# ET6801 register map
Vendor: ETMCU Inc.; File version: v0.0.1
CPU: CM7 r2p1, little endian, MPU, FPU, I-cache, D-cache, ITCM, DTCM, 4 interrupt priority bits
Registers are 32-bit, read-write, reset 0x0 unless marked. A register's access mark holds for its fields unless they carry their own. Offsets are from the block's base; [hi:lo] are bit positions; {n}, {i} and the like mark numbered series.

## AHBDMA0 (part 2 of 2) — Provide an overview of the purpose and functionality of the peripheral: hdmac_cfg
Base 0x40200000
Same registers: AHBDMA1 0x40201000
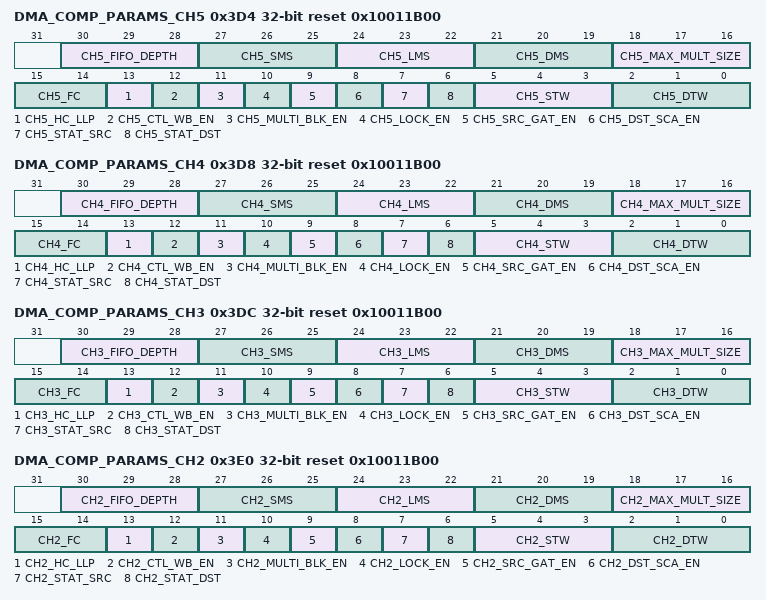
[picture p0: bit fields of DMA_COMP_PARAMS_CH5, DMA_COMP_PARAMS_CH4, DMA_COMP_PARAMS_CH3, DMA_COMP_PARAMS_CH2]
0x3D4 DMA_COMP_PARAMS_CH5 ro reset 0x10011B00 (reset mask 0xFFFFFFFE)
  [30:28] CH5_FIFO_DEPTH — Values: 0x0 (FIFO_DEPTH_8): Channel 5 FIFO depth is 8 bytes 0x1 (FIFO_DEPTH_16): Channel 5 FIFO depth is 16 bytes 0x2 (FIFO_DEPTH_32): Channel 5 FIFO depth is 32 bytes 0x3 (FIFO_DEPTH_64): Channel 5 FIFO depth is 64 bytes 0x4 (FIFO_DEPTH_128): Channel 5 FIFO depth is 128 bytes 0x5 (FIFO_DEPTH_256): Channel 5 FIFO depth is 256 bytes
  [27:25] CH5_SMS — Values: 0x0 (MASTER_1): Hardcode the AHB master 1 interface attached to the source of channel 50x1 (MASTER_2): Hardcode the AHB master 2 interface attached to the source of channel 50x2 (MASTER_3): Hardcode the AHB master 3 interface attached to the source of channel 50x3 (MASTER_4): Hardcode the AHB master 4 interface attached to the source of channel 50x4 (PROGRAMMABLE): Programmable
  [24:22] CH5_LMS — Values: 0x0 (MASTER_1): Hardcode the AHB master 1 interface attached to the LLP peripherals of channel 50x1 (MASTER_2): Hardcode the AHB master 2 interface attached to the LLP peripherals of channel 50x2 (MASTER_3): Hardcode the AHB master 3 interface attached to the LLP peripherals of channel 50x3 (MASTER_4): Hardcode the AHB master 4 interface attached to the LLP peripherals of channel 50x4 (PROGRAMMABLE): Programmable
  [21:19] CH5_DMS — Values: 0x0 (MASTER_1): Hardcode the AHB master 1 interface attached to the channel 5 destination0x1 (MASTER_2): Hardcode the AHB master 2 interface attached to the channel 5 destination0x2 (MASTER_3): Hardcode the AHB master 3 interface attached to the channel 5 destination0x3 (MASTER_4): Hardcode the AHB master 4 interface attached to the channel 5 destination0x4 (PROGRAMMABLE): Programmable
  [18:16] CH5_MAX_MULT_SIZE — Values: 0x0 (MAX_MULT_SIZE_4): Maximum value of burst transaction size that can be programmed for channel 5 is 40x1 (MAX_MULT_SIZE_8): Maximum value of burst transaction size that can be programmed for channel 5 is 80x2 (MAX_MULT_SIZE_16): Maximum value of burst transaction size that can be programmed for channel 5 is 160x3 (MAX_MULT_SIZE_32): Maximum value of burst transaction size that can be programmed for channel 5 is 320x4 (MAX_MULT_SIZE_64): Maximum value of burst transaction size that can be programmed for channel 5 is 640x5 (MAX_MULT_SIZE_128): Maximum value of burst transaction size that can be programmed for channel 5 is 1280x6 (MAX_MULT_SIZE_256): Maximum value of burst transaction size that can be programmed for channel 5 is 2560x7 (RESERVED): Reserved
  [15:14] CH5_FC — Values: 0x0 (FC_DMA): Flow controller is DMA for channel 50x1 (FC_SRC): Flow controller is Source for channel 50x2 (FC_DST): Flow controller is Destination for channel 70x3 (FC_ANY): Flow controller is ANY for channel 5
  [13] CH5_HC_LLP — Values: 0x0 (PROGRAMMABLE): Exclude logic to hardcode Channel 5 LLP register to 00x0 (HARDCODED): Hardcode Channel 5 LLP register to 0
  [12] CH5_CTL_WB_EN — Values: 0x0 (FALSE): Exclude logic to enable control register writeback after each block transfer on channel 50x1 (TRUE): Include logic to enable control register writeback after each block transfer on channel 5
  [11] CH5_MULTI_BLK_EN — Values: 0x0 (FALSE): Exclude logic to enable channel multi-block DMA transfers on channel 50x1 (TRUE): Include logic to enable channel multi-block DMA transfers on channel 5
  [10] CH5_LOCK_EN — Values: 0x0 (FALSE): Exclude logic to enable channel or bus locking on channel 50x1 (TRUE): Include logic to enable channel or bus locking on channel 5
  [9] CH5_SRC_GAT_EN — Values: 0x0 (FALSE): Exclude logic to enable the gather feature on channel 50x1 (TRUE): Include logic to enable the gather feature on channel 5
  [8] CH5_DST_SCA_EN — Values: 0x0 (FALSE): Exclude logic to enable the scatter feature on channel 50x1 (TRUE): Include logic to enable the scatter feature on channel 5
  [7] CH5_STAT_SRC — Values: 0x0 (FALSE): Exclude logic to fetch a status register from source peripheral of channel 5 and write this status information to memory at end of each block transfer0x1 (TRUE): Include logic to fetch a status register from source peripheral of channel 5 and write this status information to memory at end of each block transfer
  [6] CH5_STAT_DST — Values: 0x0 (FALSE): Exclude logic to fetch a status register from destination peripheral of channel 5 and write this status information to memory at end of each block transfer0x1 (TRUE): Include logic to fetch a status register from destination peripheral of channel 5 and write this status information to memory at end of each block transfer
  [5:3] CH5_STW — Values: 0x0 (NO_HARDCODE): No hardcode0x1 (STW_8): Hardcode the channel 5's source transfer width to 8 bits0x2 (STW_16): Hardcode the channel 5's source transfer width to 16 bits0x3 (STW_32): Hardcode the channel 5's source transfer width to 32 bits0x4 (STW_64): Hardcode the channel 5's source transfer width to 64 bits0x5 (STW_128): Hardcode the channel 5's source transfer width to 128 bits0x6 (STW_256): Hardcode the channel 5's source transfer width to 256 bits0x7 (RESERVED): Reserved
  [2:0] CH5_DTW — Values: 0x0 (NO_HARDCODE): NO Hardcode0x1 (DTW_8): Hardcode the channel 5's destination transfer width to 8 bits0x2 (DTW_16): Hardcode the channel 5's destination transfer width to 16 bits0x3 (DTW_32): Hardcode the channel 5's destination transfer width to 32 bits0x4 (DTW_64): Hardcode the channel 5's destination transfer width to 64 bits0x5 (DTW_128): Hardcode the channel 5's destination transfer width to 128 bits0x6 (DTW_256): Hardcode the channel 5's destination transfer width to 256 bits0x7 (RESERVED): Reserved
0x3D8 DMA_COMP_PARAMS_CH4 ro reset 0x10011B00 (reset mask 0xFFFFFFFE)
  [30:28] CH4_FIFO_DEPTH — Values: 0x0 (FIFO_DEPTH_8): Channel 4 FIFO depth is 8 bytes 0x1 (FIFO_DEPTH_16): Channel 4 FIFO depth is 16 bytes 0x2 (FIFO_DEPTH_32): Channel 4 FIFO depth is 32 bytes 0x3 (FIFO_DEPTH_64): Channel 4 FIFO depth is 64 bytes 0x4 (FIFO_DEPTH_128): Channel 4 FIFO depth is 128 bytes 0x5 (FIFO_DEPTH_256): Channel 4 FIFO depth is 256 bytes
  [27:25] CH4_SMS — Values: 0x0 (MASTER_1): Hardcode the AHB master 1 interface attached to the source of channel 40x1 (MASTER_2): Hardcode the AHB master 2 interface attached to the source of channel 40x2 (MASTER_3): Hardcode the AHB master 3 interface attached to the source of channel 40x3 (MASTER_4): Hardcode the AHB master 4 interface attached to the source of channel 40x4 (PROGRAMMABLE): Programmable
  [24:22] CH4_LMS — Values: 0x0 (MASTER_1): Hardcode the AHB master 1 interface attached to the LLP peripherals of channel 40x1 (MASTER_2): Hardcode the AHB master 2 interface attached to the LLP peripherals of channel 40x2 (MASTER_3): Hardcode the AHB master 3 interface attached to the LLP peripherals of channel 40x3 (MASTER_4): Hardcode the AHB master 4 interface attached to the LLP peripherals of channel 40x4 (PROGRAMMABLE): Programmable
  [21:19] CH4_DMS — Values: 0x0 (MASTER_1): Hardcode the AHB master 1 interface attached to the channel 4 destination0x1 (MASTER_2): Hardcode the AHB master 2 interface attached to the channel 4 destination0x2 (MASTER_3): Hardcode the AHB master 3 interface attached to the channel 4 destination0x3 (MASTER_4): Hardcode the AHB master 4 interface attached to the channel 4 destination0x4 (PROGRAMMABLE): Programmable
  [18:16] CH4_MAX_MULT_SIZE — Values: 0x0 (MAX_MULT_SIZE_4): Maximum value of burst transaction size that can be programmed for channel 4 is 40x1 (MAX_MULT_SIZE_8): Maximum value of burst transaction size that can be programmed for channel 4 is 80x2 (MAX_MULT_SIZE_16): Maximum value of burst transaction size that can be programmed for channel 4 is 160x3 (MAX_MULT_SIZE_32): Maximum value of burst transaction size that can be programmed for channel 4 is 320x4 (MAX_MULT_SIZE_64): Maximum value of burst transaction size that can be programmed for channel 4 is 640x5 (MAX_MULT_SIZE_128): Maximum value of burst transaction size that can be programmed for channel 4 is 1280x6 (MAX_MULT_SIZE_256): Maximum value of burst transaction size that can be programmed for channel 4 is 2560x7 (RESERVED): Reserved
  [15:14] CH4_FC — Values: 0x0 (FC_DMA): Flow controller is DMA for channel 40x1 (FC_SRC): Flow controller is Source for channel 40x2 (FC_DST): Flow controller is Destination for channel 70x3 (FC_ANY): Flow controller is ANY for channel 4
  [13] CH4_HC_LLP — Values: 0x0 (PROGRAMMABLE): Exclude logic to hardcode Channel 4 LLP register to 00x0 (HARDCODED): Hardcode Channel 4 LLP register to 0
  [12] CH4_CTL_WB_EN — Values: 0x0 (FALSE): Exclude logic to enable control register writeback after each block transfer on channel 40x1 (TRUE): Include logic to enable control register writeback after each block transfer on channel 4
  [11] CH4_MULTI_BLK_EN — Values: 0x0 (FALSE): Exclude logic to enable channel multi-block DMA transfers on channel 40x1 (TRUE): Include logic to enable channel multi-block DMA transfers on channel 4
  [10] CH4_LOCK_EN — Values: 0x0 (FALSE): Exclude logic to enable channel or bus locking on channel 40x1 (TRUE): Include logic to enable channel or bus locking on channel 4
  [9] CH4_SRC_GAT_EN — Values: 0x0 (FALSE): Exclude logic to enable the gather feature on channel 40x1 (TRUE): Include logic to enable the gather feature on channel 4
  [8] CH4_DST_SCA_EN — Values: 0x0 (FALSE): Exclude logic to enable the scatter feature on channel 40x1 (TRUE): Include logic to enable the scatter feature on channel 4
  [7] CH4_STAT_SRC — Values: 0x0 (FALSE): Exclude logic to fetch a status register from source peripheral of channel 4 and write this status information to memory at end of each block transfer0x1 (TRUE): Include logic to fetch a status register from source peripheral of channel 4 and write this status information to memory at end of each block transfer
  [6] CH4_STAT_DST — Values: 0x0 (FALSE): Exclude logic to fetch a status register from destination peripheral of channel 4 and write this status information to memory at end of each block transfer0x1 (TRUE): Include logic to fetch a status register from destination peripheral of channel 4 and write this status information to memory at end of each block transfer
  [5:3] CH4_STW — Values: 0x0 (NO_HARDCODE): No hardcode0x1 (STW_8): Hardcode the channel 4's source transfer width to 8 bits0x2 (STW_16): Hardcode the channel 4's source transfer width to 16 bits0x3 (STW_32): Hardcode the channel 4's source transfer width to 32 bits0x4 (STW_64): Hardcode the channel 4's source transfer width to 64 bits0x5 (STW_128): Hardcode the channel 4's source transfer width to 128 bits0x6 (STW_256): Hardcode the channel 4's source transfer width to 256 bits0x7 (RESERVED): Reserved
  [2:0] CH4_DTW — Values: 0x0 (NO_HARDCODE): NO Hardcode0x1 (DTW_8): Hardcode the channel 4's destination transfer width to 8 bits0x2 (DTW_16): Hardcode the channel 4's destination transfer width to 16 bits0x3 (DTW_32): Hardcode the channel 4's destination transfer width to 32 bits0x4 (DTW_64): Hardcode the channel 4's destination transfer width to 64 bits0x5 (DTW_128): Hardcode the channel 4's destination transfer width to 128 bits0x6 (DTW_256): Hardcode the channel 4's destination transfer width to 256 bits0x7 (RESERVED): Reserved
0x3DC DMA_COMP_PARAMS_CH3 ro reset 0x10011B00 (reset mask 0xFFFFFFFE)
  [30:28] CH3_FIFO_DEPTH — Values: 0x0 (FIFO_DEPTH_8): Channel 3 FIFO depth is 8 bytes 0x1 (FIFO_DEPTH_16): Channel 3 FIFO depth is 16 bytes 0x2 (FIFO_DEPTH_32): Channel 3 FIFO depth is 32 bytes 0x3 (FIFO_DEPTH_64): Channel 3 FIFO depth is 64 bytes 0x4 (FIFO_DEPTH_128): Channel 3 FIFO depth is 128 bytes 0x5 (FIFO_DEPTH_256): Channel 3 FIFO depth is 256 bytes
  [27:25] CH3_SMS — Values: 0x0 (MASTER_1): Hardcode the AHB master 1 interface attached to the source of channel 30x1 (MASTER_2): Hardcode the AHB master 2 interface attached to the source of channel 30x2 (MASTER_3): Hardcode the AHB master 3 interface attached to the source of channel 30x3 (MASTER_4): Hardcode the AHB master 4 interface attached to the source of channel 30x4 (PROGRAMMABLE): Programmable
  [24:22] CH3_LMS — Values: 0x0 (MASTER_1): Hardcode the AHB master 1 interface attached to the LLP peripherals of channel 30x1 (MASTER_2): Hardcode the AHB master 2 interface attached to the LLP peripherals of channel 30x2 (MASTER_3): Hardcode the AHB master 3 interface attached to the LLP peripherals of channel 30x3 (MASTER_4): Hardcode the AHB master 4 interface attached to the LLP peripherals of channel 30x4 (PROGRAMMABLE): Programmable
  [21:19] CH3_DMS — Values: 0x0 (MASTER_1): Hardcode the AHB master 1 interface attached to the channel 3 destination0x1 (MASTER_2): Hardcode the AHB master 2 interface attached to the channel 3 destination0x2 (MASTER_3): Hardcode the AHB master 3 interface attached to the channel 3 destination0x3 (MASTER_4): Hardcode the AHB master 4 interface attached to the channel 3 destination0x4 (PROGRAMMABLE): Programmable
  [18:16] CH3_MAX_MULT_SIZE — Values: 0x0 (MAX_MULT_SIZE_4): Maximum value of burst transaction size that can be programmed for channel 3 is 40x1 (MAX_MULT_SIZE_8): Maximum value of burst transaction size that can be programmed for channel 3 is 80x2 (MAX_MULT_SIZE_16): Maximum value of burst transaction size that can be programmed for channel 3 is 160x3 (MAX_MULT_SIZE_32): Maximum value of burst transaction size that can be programmed for channel 3 is 320x4 (MAX_MULT_SIZE_64): Maximum value of burst transaction size that can be programmed for channel 3 is 640x5 (MAX_MULT_SIZE_128): Maximum value of burst transaction size that can be programmed for channel 3 is 1280x6 (MAX_MULT_SIZE_256): Maximum value of burst transaction size that can be programmed for channel 3 is 2560x7 (RESERVED): Reserved
  [15:14] CH3_FC — Values: 0x0 (FC_DMA): Flow controller is DMA for channel 30x1 (FC_SRC): Flow controller is Source for channel 30x2 (FC_DST): Flow controller is Destination for channel 70x3 (FC_ANY): Flow controller is ANY for channel 3
  [13] CH3_HC_LLP — Values: 0x0 (PROGRAMMABLE): Exclude logic to hardcode Channel 3 LLP register to 00x0 (HARDCODED): Hardcode Channel 3 LLP register to 0
  [12] CH3_CTL_WB_EN — Values: 0x0 (FALSE): Exclude logic to enable control register writeback after each block transfer on channel 30x1 (TRUE): Include logic to enable control register writeback after each block transfer on channel 3
  [11] CH3_MULTI_BLK_EN — Values: 0x0 (FALSE): Exclude logic to enable channel multi-block DMA transfers on channel 30x1 (TRUE): Include logic to enable channel multi-block DMA transfers on channel 3
  [10] CH3_LOCK_EN — Values: 0x0 (FALSE): Exclude logic to enable channel or bus locking on channel 30x1 (TRUE): Include logic to enable channel or bus locking on channel 3
  [9] CH3_SRC_GAT_EN — Values: 0x0 (FALSE): Exclude logic to enable the gather feature on channel 30x1 (TRUE): Include logic to enable the gather feature on channel 3
  [8] CH3_DST_SCA_EN — Values: 0x0 (FALSE): Exclude logic to enable the scatter feature on channel 30x1 (TRUE): Include logic to enable the scatter feature on channel 3
  [7] CH3_STAT_SRC — Values: 0x0 (FALSE): Exclude logic to fetch a status register from source peripheral of channel 3 and write this status information to memory at end of each block transfer0x1 (TRUE): Include logic to fetch a status register from source peripheral of channel 3 and write this status information to memory at end of each block transfer
  [6] CH3_STAT_DST — Values: 0x0 (FALSE): Exclude logic to fetch a status register from destination peripheral of channel 3 and write this status information to memory at end of each block transfer0x1 (TRUE): Include logic to fetch a status register from destination peripheral of channel 3 and write this status information to memory at end of each block transfer
  [5:3] CH3_STW — Values: 0x0 (NO_HARDCODE): No hardcode0x1 (STW_8): Hardcode the channel 3's source transfer width to 8 bits0x2 (STW_16): Hardcode the channel 3's source transfer width to 16 bits0x3 (STW_32): Hardcode the channel 3's source transfer width to 32 bits0x4 (STW_64): Hardcode the channel 3's source transfer width to 64 bits0x5 (STW_128): Hardcode the channel 3's source transfer width to 128 bits0x6 (STW_256): Hardcode the channel 3's source transfer width to 256 bits0x7 (RESERVED): Reserved
  [2:0] CH3_DTW — Values: 0x0 (NO_HARDCODE): NO Hardcode0x1 (DTW_8): Hardcode the channel 3's destination transfer width to 8 bits0x2 (DTW_16): Hardcode the channel 3's destination transfer width to 16 bits0x3 (DTW_32): Hardcode the channel 3's destination transfer width to 32 bits0x4 (DTW_64): Hardcode the channel 3's destination transfer width to 64 bits0x5 (DTW_128): Hardcode the channel 3's destination transfer width to 128 bits0x6 (DTW_256): Hardcode the channel 3's destination transfer width to 256 bits0x7 (RESERVED): Reserved
0x3E0 DMA_COMP_PARAMS_CH2 ro reset 0x10011B00 (reset mask 0xFFFFFFFE)
  [30:28] CH2_FIFO_DEPTH — Values: 0x0 (FIFO_DEPTH_8): Channel 2 FIFO depth is 8 bytes 0x1 (FIFO_DEPTH_16): Channel 2 FIFO depth is 16 bytes 0x2 (FIFO_DEPTH_32): Channel 2 FIFO depth is 32 bytes 0x3 (FIFO_DEPTH_64): Channel 2 FIFO depth is 64 bytes 0x4 (FIFO_DEPTH_128): Channel 2 FIFO depth is 128 bytes 0x5 (FIFO_DEPTH_256): Channel 2 FIFO depth is 256 bytes
  [27:25] CH2_SMS — Values: 0x0 (MASTER_1): Hardcode the AHB master 1 interface attached to the source of channel 20x1 (MASTER_2): Hardcode the AHB master 2 interface attached to the source of channel 20x2 (MASTER_3): Hardcode the AHB master 3 interface attached to the source of channel 20x3 (MASTER_4): Hardcode the AHB master 4 interface attached to the source of channel 20x4 (PROGRAMMABLE): Programmable
  [24:22] CH2_LMS — Values: 0x0 (MASTER_1): Hardcode the AHB master 1 interface attached to the LLP peripherals of channel 20x1 (MASTER_2): Hardcode the AHB master 2 interface attached to the LLP peripherals of channel 20x2 (MASTER_3): Hardcode the AHB master 3 interface attached to the LLP peripherals of channel 20x3 (MASTER_4): Hardcode the AHB master 4 interface attached to the LLP peripherals of channel 20x4 (PROGRAMMABLE): Programmable
  [21:19] CH2_DMS — Values: 0x0 (MASTER_1): Hardcode the AHB master 1 interface attached to the channel 2 destination0x1 (MASTER_2): Hardcode the AHB master 2 interface attached to the channel 2 destination0x2 (MASTER_3): Hardcode the AHB master 3 interface attached to the channel 2 destination0x3 (MASTER_4): Hardcode the AHB master 4 interface attached to the channel 2 destination0x4 (PROGRAMMABLE): Programmable
  [18:16] CH2_MAX_MULT_SIZE — Values: 0x0 (MAX_MULT_SIZE_4): Maximum value of burst transaction size that can be programmed for channel 2 is 40x1 (MAX_MULT_SIZE_8): Maximum value of burst transaction size that can be programmed for channel 2 is 80x2 (MAX_MULT_SIZE_16): Maximum value of burst transaction size that can be programmed for channel 2 is 160x3 (MAX_MULT_SIZE_32): Maximum value of burst transaction size that can be programmed for channel 2 is 320x4 (MAX_MULT_SIZE_64): Maximum value of burst transaction size that can be programmed for channel 2 is 640x5 (MAX_MULT_SIZE_128): Maximum value of burst transaction size that can be programmed for channel 2 is 1280x6 (MAX_MULT_SIZE_256): Maximum value of burst transaction size that can be programmed for channel 2 is 2560x7 (RESERVED): Reserved
  [15:14] CH2_FC — Values: 0x0 (FC_DMA): Flow controller is DMA for channel 20x1 (FC_SRC): Flow controller is Source for channel 20x2 (FC_DST): Flow controller is Destination for channel 70x3 (FC_ANY): Flow controller is ANY for channel 2
  [13] CH2_HC_LLP — Values: 0x0 (PROGRAMMABLE): Exclude logic to hardcode Channel 2 LLP register to 00x0 (HARDCODED): Hardcode Channel 2 LLP register to 0
  [12] CH2_CTL_WB_EN — Values: 0x0 (FALSE): Exclude logic to enable control register writeback after each block transfer on channel 20x1 (TRUE): Include logic to enable control register writeback after each block transfer on channel 2
  [11] CH2_MULTI_BLK_EN — Values: 0x0 (FALSE): Exclude logic to enable channel multi-block DMA transfers on channel 20x1 (TRUE): Include logic to enable channel multi-block DMA transfers on channel 2
  [10] CH2_LOCK_EN — Values: 0x0 (FALSE): Exclude logic to enable channel or bus locking on channel 20x1 (TRUE): Include logic to enable channel or bus locking on channel 2
  [9] CH2_SRC_GAT_EN — Values: 0x0 (FALSE): Exclude logic to enable the gather feature on channel 20x1 (TRUE): Include logic to enable the gather feature on channel 2
  [8] CH2_DST_SCA_EN — Values: 0x0 (FALSE): Exclude logic to enable the scatter feature on channel 20x1 (TRUE): Include logic to enable the scatter feature on channel 2
  [7] CH2_STAT_SRC — Values: 0x0 (FALSE): Exclude logic to fetch a status register from source peripheral of channel 2 and write this status information to memory at end of each block transfer0x1 (TRUE): Include logic to fetch a status register from source peripheral of channel 2 and write this status information to memory at end of each block transfer
  [6] CH2_STAT_DST — Values: 0x0 (FALSE): Exclude logic to fetch a status register from destination peripheral of channel 2 and write this status information to memory at end of each block transfer0x1 (TRUE): Include logic to fetch a status register from destination peripheral of channel 2 and write this status information to memory at end of each block transfer
  [5:3] CH2_STW — Values: 0x0 (NO_HARDCODE): No hardcode0x1 (STW_8): Hardcode the channel 2's source transfer width to 8 bits0x2 (STW_16): Hardcode the channel 2's source transfer width to 16 bits0x3 (STW_32): Hardcode the channel 2's source transfer width to 32 bits0x4 (STW_64): Hardcode the channel 2's source transfer width to 64 bits0x5 (STW_128): Hardcode the channel 2's source transfer width to 128 bits0x6 (STW_256): Hardcode the channel 2's source transfer width to 256 bits0x7 (RESERVED): Reserved
  [2:0] CH2_DTW — Values: 0x0 (NO_HARDCODE): NO Hardcode0x1 (DTW_8): Hardcode the channel 2's destination transfer width to 8 bits0x2 (DTW_16): Hardcode the channel 2's destination transfer width to 16 bits0x3 (DTW_32): Hardcode the channel 2's destination transfer width to 32 bits0x4 (DTW_64): Hardcode the channel 2's destination transfer width to 64 bits0x5 (DTW_128): Hardcode the channel 2's destination transfer width to 128 bits0x6 (DTW_256): Hardcode the channel 2's destination transfer width to 256 bits0x7 (RESERVED): Reserved
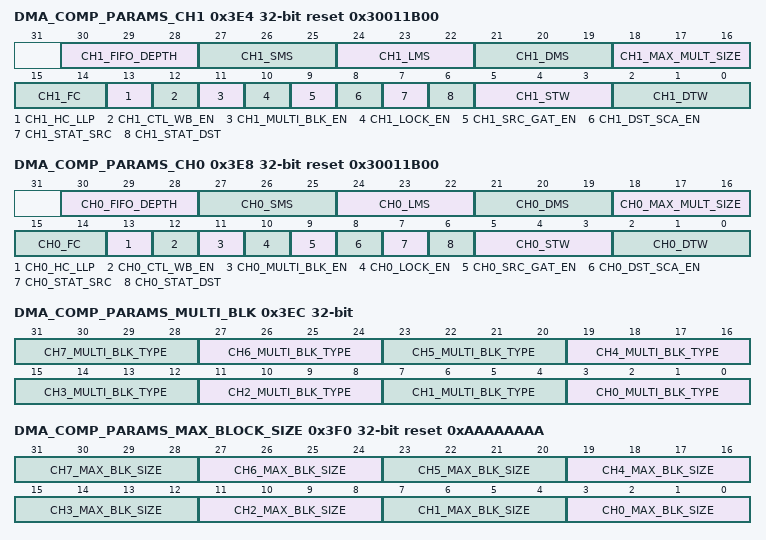
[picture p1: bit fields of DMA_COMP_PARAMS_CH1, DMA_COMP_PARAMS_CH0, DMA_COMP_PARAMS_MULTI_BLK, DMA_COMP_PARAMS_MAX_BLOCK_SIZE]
0x3E4 DMA_COMP_PARAMS_CH1 ro reset 0x30011B00 (reset mask 0xFFFFFFFE)
  [30:28] CH1_FIFO_DEPTH — Values: 0x0 (FIFO_DEPTH_8): Channel 1 FIFO depth is 8 bytes 0x1 (FIFO_DEPTH_16): Channel 1 FIFO depth is 16 bytes 0x2 (FIFO_DEPTH_32): Channel 1 FIFO depth is 32 bytes 0x3 (FIFO_DEPTH_64): Channel 1 FIFO depth is 64 bytes 0x4 (FIFO_DEPTH_128): Channel 1 FIFO depth is 128 bytes 0x5 (FIFO_DEPTH_256): Channel 1 FIFO depth is 256 bytes
  [27:25] CH1_SMS — Values: 0x0 (MASTER_1): Hardcode the AHB master 1 interface attached to the source of channel 10x1 (MASTER_2): Hardcode the AHB master 2 interface attached to the source of channel 10x2 (MASTER_3): Hardcode the AHB master 3 interface attached to the source of channel 10x3 (MASTER_4): Hardcode the AHB master 4 interface attached to the source of channel 10x4 (PROGRAMMABLE): Programmable
  [24:22] CH1_LMS — Values: 0x0 (MASTER_1): Hardcode the AHB master 1 interface attached to the LLP peripherals of channel 10x1 (MASTER_2): Hardcode the AHB master 2 interface attached to the LLP peripherals of channel 10x2 (MASTER_3): Hardcode the AHB master 3 interface attached to the LLP peripherals of channel 10x3 (MASTER_4): Hardcode the AHB master 4 interface attached to the LLP peripherals of channel 10x4 (PROGRAMMABLE): Programmable
  [21:19] CH1_DMS — Values: 0x0 (MASTER_1): Hardcode the AHB master 1 interface attached to the channel 1 destination0x1 (MASTER_2): Hardcode the AHB master 2 interface attached to the channel 1 destination0x2 (MASTER_3): Hardcode the AHB master 3 interface attached to the channel 1 destination0x3 (MASTER_4): Hardcode the AHB master 4 interface attached to the channel 1 destination0x4 (PROGRAMMABLE): Programmable
  [18:16] CH1_MAX_MULT_SIZE — Values: 0x0 (MAX_MULT_SIZE_4): Maximum value of burst transaction size that can be programmed for channel 1 is 40x1 (MAX_MULT_SIZE_8): Maximum value of burst transaction size that can be programmed for channel 1 is 80x2 (MAX_MULT_SIZE_16): Maximum value of burst transaction size that can be programmed for channel 1 is 160x3 (MAX_MULT_SIZE_32): Maximum value of burst transaction size that can be programmed for channel 1 is 320x4 (MAX_MULT_SIZE_64): Maximum value of burst transaction size that can be programmed for channel 1 is 640x5 (MAX_MULT_SIZE_128): Maximum value of burst transaction size that can be programmed for channel 1 is 1280x6 (MAX_MULT_SIZE_256): Maximum value of burst transaction size that can be programmed for channel 1 is 2560x7 (RESERVED): Reserved
  [15:14] CH1_FC — Values: 0x0 (FC_DMA): Flow controller is DMA for channel 10x1 (FC_SRC): Flow controller is Source for channel 10x2 (FC_DST): Flow controller is Destination for channel 70x3 (FC_ANY): Flow controller is ANY for channel 1
  [13] CH1_HC_LLP — Values: 0x0 (PROGRAMMABLE): Exclude logic to hardcode Channel 1 LLP register to 00x0 (HARDCODED): Hardcode Channel 1 LLP register to 0
  [12] CH1_CTL_WB_EN — Values: 0x0 (FALSE): Exclude logic to enable control register writeback after each block transfer on channel 10x1 (TRUE): Include logic to enable control register writeback after each block transfer on channel 1
  [11] CH1_MULTI_BLK_EN — Values: 0x0 (FALSE): Exclude logic to enable channel multi-block DMA transfers on channel 10x1 (TRUE): Include logic to enable channel multi-block DMA transfers on channel 1
  [10] CH1_LOCK_EN — Values: 0x0 (FALSE): Exclude logic to enable channel or bus locking on channel 10x1 (TRUE): Include logic to enable channel or bus locking on channel 1
  [9] CH1_SRC_GAT_EN — Values: 0x0 (FALSE): Exclude logic to enable the gather feature on channel 10x1 (TRUE): Include logic to enable the gather feature on channel 1
  [8] CH1_DST_SCA_EN — Values: 0x0 (FALSE): Exclude logic to enable the scatter feature on channel 10x1 (TRUE): Include logic to enable the scatter feature on channel 1
  [7] CH1_STAT_SRC — Values: 0x0 (FALSE): Exclude logic to fetch a status register from source peripheral of channel 1 and write this status information to memory at end of each block transfer0x1 (TRUE): Include logic to fetch a status register from source peripheral of channel 1 and write this status information to memory at end of each block transfer
  [6] CH1_STAT_DST — Values: 0x0 (FALSE): Exclude logic to fetch a status register from destination peripheral of channel 1 and write this status information to memory at end of each block transfer0x1 (TRUE): Include logic to fetch a status register from destination peripheral of channel 1 and write this status information to memory at end of each block transfer
  [5:3] CH1_STW — Values: 0x0 (NO_HARDCODE): No hardcode0x1 (STW_8): Hardcode the channel 1's source transfer width to 8 bits0x2 (STW_16): Hardcode the channel 1's source transfer width to 16 bits0x3 (STW_32): Hardcode the channel 1's source transfer width to 32 bits0x4 (STW_64): Hardcode the channel 1's source transfer width to 64 bits0x5 (STW_128): Hardcode the channel 1's source transfer width to 128 bits0x6 (STW_256): Hardcode the channel 1's source transfer width to 256 bits0x7 (RESERVED): Reserved
  [2:0] CH1_DTW — Values: 0x0 (NO_HARDCODE): NO Hardcode0x1 (DTW_8): Hardcode the channel 1's destination transfer width to 8 bits0x2 (DTW_16): Hardcode the channel 1's destination transfer width to 16 bits0x3 (DTW_32): Hardcode the channel 1's destination transfer width to 32 bits0x4 (DTW_64): Hardcode the channel 1's destination transfer width to 64 bits0x5 (DTW_128): Hardcode the channel 1's destination transfer width to 128 bits0x6 (DTW_256): Hardcode the channel 1's destination transfer width to 256 bits0x7 (RESERVED): Reserved
0x3E8 DMA_COMP_PARAMS_CH0 ro reset 0x30011B00 (reset mask 0xFFFFFFFE)
  [30:28] CH0_FIFO_DEPTH — Values: 0x0 (FIFO_DEPTH_8): Channel 0 FIFO depth is 8 bytes 0x1 (FIFO_DEPTH_16): Channel 0 FIFO depth is 16 bytes 0x2 (FIFO_DEPTH_32): Channel 0 FIFO depth is 32 bytes 0x3 (FIFO_DEPTH_64): Channel 0 FIFO depth is 64 bytes 0x4 (FIFO_DEPTH_128): Channel 0 FIFO depth is 128 bytes 0x5 (FIFO_DEPTH_256): Channel 0 FIFO depth is 256 bytes
  [27:25] CH0_SMS — Values: 0x0 (MASTER_1): Hardcode the AHB master 1 interface attached to the source of channel 00x1 (MASTER_2): Hardcode the AHB master 2 interface attached to the source of channel 00x2 (MASTER_3): Hardcode the AHB master 3 interface attached to the source of channel 00x3 (MASTER_4): Hardcode the AHB master 4 interface attached to the source of channel 00x4 (PROGRAMMABLE): Programmable
  [24:22] CH0_LMS — Values: 0x0 (MASTER_1): Hardcode the AHB master 1 interface attached to the LLP peripherals of channel 00x1 (MASTER_2): Hardcode the AHB master 2 interface attached to the LLP peripherals of channel 00x2 (MASTER_3): Hardcode the AHB master 3 interface attached to the LLP peripherals of channel 00x3 (MASTER_4): Hardcode the AHB master 4 interface attached to the LLP peripherals of channel 00x4 (PROGRAMMABLE): Programmable
  [21:19] CH0_DMS — Values: 0x0 (MASTER_1): Hardcode the AHB master 1 interface attached to the channel 0 destination0x1 (MASTER_2): Hardcode the AHB master 2 interface attached to the channel 0 destination0x2 (MASTER_3): Hardcode the AHB master 3 interface attached to the channel 0 destination0x3 (MASTER_4): Hardcode the AHB master 4 interface attached to the channel 0 destination0x4 (PROGRAMMABLE): Programmable
  [18:16] CH0_MAX_MULT_SIZE — Values: 0x0 (MAX_MULT_SIZE_4): Maximum value of burst transaction size that can be programmed for channel 0 is 40x1 (MAX_MULT_SIZE_8): Maximum value of burst transaction size that can be programmed for channel 0 is 80x2 (MAX_MULT_SIZE_16): Maximum value of burst transaction size that can be programmed for channel 0 is 160x3 (MAX_MULT_SIZE_32): Maximum value of burst transaction size that can be programmed for channel 0 is 320x4 (MAX_MULT_SIZE_64): Maximum value of burst transaction size that can be programmed for channel 0 is 640x5 (MAX_MULT_SIZE_128): Maximum value of burst transaction size that can be programmed for channel 0 is 1280x6 (MAX_MULT_SIZE_256): Maximum value of burst transaction size that can be programmed for channel 0 is 2560x7 (RESERVED): Reserved
  [15:14] CH0_FC — Values: 0x0 (FC_DMA): Flow controller is DMA for channel 00x1 (FC_SRC): Flow controller is Source for channel 00x2 (FC_DST): Flow controller is Destination for channel 70x3 (FC_ANY): Flow controller is ANY for channel 0
  [13] CH0_HC_LLP — Values: 0x0 (PROGRAMMABLE): Exclude logic to hardcode Channel 0 LLP register to 00x0 (HARDCODED): Hardcode Channel 0 LLP register to 0
  [12] CH0_CTL_WB_EN — Values: 0x0 (FALSE): Exclude logic to enable control register writeback after each block transfer on channel 00x1 (TRUE): Include logic to enable control register writeback after each block transfer on channel 0
  [11] CH0_MULTI_BLK_EN — Values: 0x0 (FALSE): Exclude logic to enable channel multi-block DMA transfers on channel 00x1 (TRUE): Include logic to enable channel multi-block DMA transfers on channel 0
  [10] CH0_LOCK_EN — Values: 0x0 (FALSE): Exclude logic to enable channel or bus locking on channel 00x1 (TRUE): Include logic to enable channel or bus locking on channel 0
  [9] CH0_SRC_GAT_EN — Values: 0x0 (FALSE): Exclude logic to enable the gather feature on channel 00x1 (TRUE): Include logic to enable the gather feature on channel 0
  [8] CH0_DST_SCA_EN — Values: 0x0 (FALSE): Exclude logic to enable the scatter feature on channel 00x1 (TRUE): Include logic to enable the scatter feature on channel 0
  [7] CH0_STAT_SRC — Values: 0x0 (FALSE): Exclude logic to fetch a status register from source peripheral of channel 0 and write this status information to memory at end of each block transfer0x1 (TRUE): Include logic to fetch a status register from source peripheral of channel 0 and write this status information to memory at end of each block transfer
  [6] CH0_STAT_DST — Values: 0x0 (FALSE): Exclude logic to fetch a status register from destination peripheral of channel 0 and write this status information to memory at end of each block transfer0x1 (TRUE): Include logic to fetch a status register from destination peripheral of channel 0 and write this status information to memory at end of each block transfer
  [5:3] CH0_STW — Values: 0x0 (NO_HARDCODE): No hardcode0x1 (STW_8): Hardcode the channel 0's source transfer width to 8 bits0x2 (STW_16): Hardcode the channel 0's source transfer width to 16 bits0x3 (STW_32): Hardcode the channel 0's source transfer width to 32 bits0x4 (STW_64): Hardcode the channel 0's source transfer width to 64 bits0x5 (STW_128): Hardcode the channel 0's source transfer width to 128 bits0x6 (STW_256): Hardcode the channel 0's source transfer width to 256 bits0x7 (RESERVED): Reserved
  [2:0] CH0_DTW — Values: 0x0 (NO_HARDCODE): NO Hardcode0x1 (DTW_8): Hardcode the channel 0's destination transfer width to 8 bits0x2 (DTW_16): Hardcode the channel 0's destination transfer width to 16 bits0x3 (DTW_32): Hardcode the channel 0's destination transfer width to 32 bits0x4 (DTW_64): Hardcode the channel 0's destination transfer width to 64 bits0x5 (DTW_128): Hardcode the channel 0's destination transfer width to 128 bits0x6 (DTW_256): Hardcode the channel 0's destination transfer width to 256 bits0x7 (RESERVED): Reserved
0x3EC DMA_COMP_PARAMS_MULTI_BLK ro
  [4n+3:4n] CH{n}_MULTI_BLK_TYPE (n=0..7) — Values: 0x0 (PROGRAMMABLE): Allow all types of multi-support0x1 (CONT_RELOAD): Allow only multi-block transfers where SAR{n} is contiguous; DAR and CTL are reloaded from their initial values0x2 (RELOAD_CONT): Allow only multi-block transfers where SAR{n} and CTL{n} are reloaded from their initial values; DAR{n} is contiguous0x3 (RELOAD_RELOAD): Allow only multi-block transfers where SAR{n}, DAR{n},and CTL{n} are reloaded from their initial values0x4 (CONT_LLP): Allow only multi-block transfers where SAR{n} is contiguous;DAR{n}, CTL{n}, and LLP{n} are loaded from the next linked list item0x5 (RELOAD_LLP): Allow only multi-block transfers where SAR{n} is reloaded from its initial value; DAR{n}, CTL{n}, and LLP{n},are loaded from the next linked list item0x6 (CNT_LLP): Allow only multi-block transfers where SAR{n}, CTL{n}, and LLP{n} are loaded from the next linked list item; DARx is contiguous0x7 (LLP_RELOAD): Allow only multi-block transfers where SAR{n}, CTL{n}, and LLP{n},are loaded from the next linked list item; DARx is reloaded from its initial values.0x8 (LLP_LLP): Allow only multi-block transfers where SAR{n}, DAR{n}, CTL{n}, and LLP{n} are loaded from the next linked list item.
0x3F0 DMA_COMP_PARAMS_MAX_BLOCK_SIZE ro reset 0xAAAAAAAA
  [4n+3:4n] CH{n}_MAX_BLK_SIZE (n=0..7) — Values: 0x0 (MAX_BLOCK_SIZE_3): Maximum block size in source transfer widths is 3 for channel {10n:02}x1 (MAX_BLOCK_SIZE_7): Maximum block size in source transfer widths is 7 for channel {10n:02}x2 (MAX_BLOCK_SIZE_15): Maximum block size in source transfer widths is 15 for channel {10n:02}x3 (MAX_BLOCK_SIZE_31): Maximum block size in source transfer widths is 31 for channel {10n:02}x4 (MAX_BLOCK_SIZE_63): Maximum block size in source transfer widths is 63 for channel {10n:02}x5 (MAX_BLOCK_SIZE_127): Maximum block size in source transfer widths is 127 for channel {10n:02}x6 (MAX_BLOCK_SIZE_255): Maximum block size in source transfer widths is 255 for channel {10n:02}x7 (MAX_BLOCK_SIZE_511): Maximum block size in source transfer widths is 511 for channel {10n:02}x8 (MAX_BLOCK_SIZE_1023): Maximum block size in source transfer widths is 1023 for channel {10n:02}x9 (MAX_BLOCK_SIZE_2047): Maximum block size in source transfer widths is 2047 for channel {10n:02}xa (MAX_BLOCK_SIZE_4095): Maximum block size in source transfer widths is 4095 for channel {n}
0x3F8 DMACOMPSID ro reset 0x44571110
  [31:0] DMA_COMP_TYPE — DMA Component Type Number = `h44571110. This assigned unique hex value is constant and is derived from the two ASCII letters "DW" followed by a 32-bit unsigned number
